# PY32T020xx register map
Vendor: Puya; Series: PY32L0; File version: 1.0.0
CPU: CM0+ r0p1, little endian, no MPU, no FPU, 4 interrupt priority bits
Registers are 32-bit, read-write, reset 0x0 unless marked. A register's access mark holds for its fields unless they carry their own. Offsets are from the block's base; [hi:lo] are bit positions; {n}, {i} and the like mark numbered series.

## PWR — Power control
Base 0x40007000
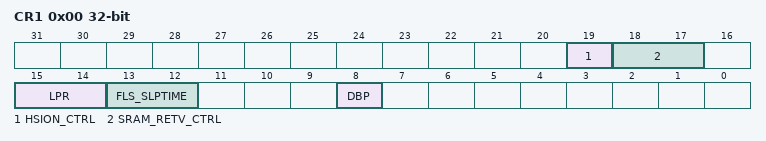
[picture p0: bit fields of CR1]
0x00 CR1 — Power control register 1
  [19] HSION_CTRL
  [18:17] SRAM_RETV_CTRL — sram retev control
  [15:14] LPR — pmu mode control
  [13:12] FLS_SLPTIME — flash sleep time control
  [8] DBP — dbg mode protect enable

## RTC — Real time clock
Base 0x40002800
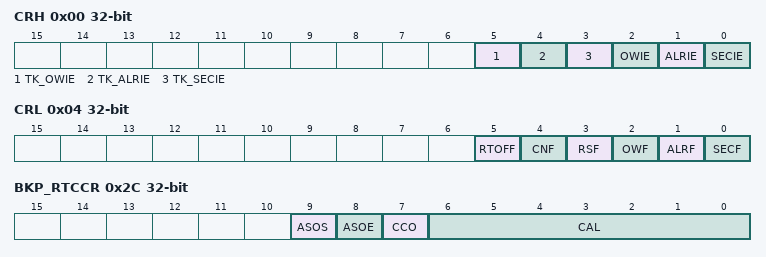
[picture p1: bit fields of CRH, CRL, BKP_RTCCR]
0x00 CRH — RTC Control Register High
  [5] TK_OWIE — TK overflow interrupt allowable bits
  [4] TK_ALRIE — TK alarm interrupt allowed bits
  [3] TK_SECIE — TK sec interrupt allowable bits
  [2] OWIE — Overflow interrupt allow bits
  [1] ALRIE — Alarm interrupt allowed bits
  [0] SECIE — Seconds interrupt allowed bits
0x04 CRL — RTC Control Register Low
  [5] RTOFF ro — RTC operation OFF
  [4] CNF — Configuration flag
  [3] RSF — Registers synchronized flag
  [2] OWF — Overflow flag
  [1] ALRF — Alarm flag
  [0] SECF — Second flag
0x08 PRLH — RTC Prescaler Load Register High
  [5:0] PRL wo — RTC prescaler reload value high
0x0C PRLL — RTC Prescaler Load Register Low
  [15:0] PRL wo — RTC prescaler reload value high
0x10 DIVH — RTC Prescaler Divider Register High
  [3:0] RTC_DIV ro — RTC clock divider
0x14 DIVL — RTC Prescaler Divider Register Low
  [15:0] RTC_DIV ro — RTC clock divider
0x18 CNTH — RTC Counter Register High
  [15:0] RTC_CNT — RTC core counter
0x1C CNTL — RTC Counter Register Low
  [15:0] RTC_CNT — RTC core counter
0x20 ALRH — RTC Alarm Register High
  [15:0] ALR — RTC alarm value
0x24 ALRL — RTC Alarm Register Low
  [15:0] ALR — RTC alarm value
0x2C BKP_RTCCR
  [9] ASOS — Seconds/alarm pulse output select bits
  [8] ASOE — Seconds/alarm pulse output enable bit
  [7] CCO — Calibrate the clock output bits
  [6:0] CAL — Calibration value

## SPI1 — Serial peripheral interface
Base 0x40013000
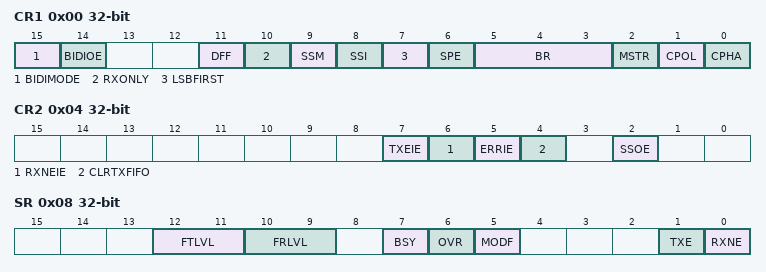
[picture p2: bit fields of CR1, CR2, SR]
0x00 CR1
  [15] BIDIMODE — Bidirectional data mode enable
  [14] BIDIOE — Output enable in bidirectional mode
  [11] DFF — Data frame format
  [10] RXONLY — Receive only
  [9] SSM — Software slave management
  [8] SSI — Internal slave select
  [7] LSBFIRST — Frame Format
  [6] SPE — SPI Enable
  [5:3] BR — Baud Rate Control
  [2] MSTR — Master Selection
  [1] CPOL — Clock Polarity
  [0] CPHA — Clock Phase
0x04 CR2
  [7] TXEIE — Tx buffer Empty Interrupt Enable
  [6] RXNEIE — RX buffer Not Empty Interrupt Enable
  [5] ERRIE — Error Interrupt Enable
  [4] CLRTXFIFO — Clear FIFO
  [2] SSOE — SS Output Enable
0x08 SR
  [12:11] FTLVL ro — FIFO Transmission Level
  [10:9] FRLVL ro — FIFO Reception Level
  [7] BSY ro — Busy flag
  [6] OVR ro — Overrun flag
  [5] MODF — Mode fault
  [1] TXE ro — Transmit buffer Empty
  [0] RXNE ro — Receive buffer Not Empty
0x0C DR
  [15:0] DR — Data Register

## SYSCFG — System configuration controller
Base 0x40010000
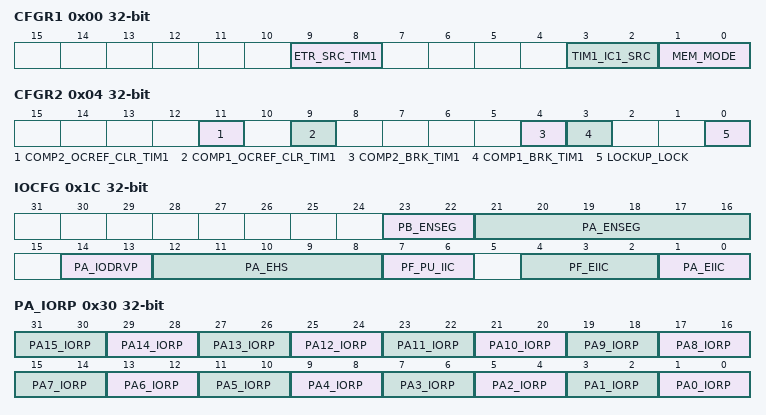
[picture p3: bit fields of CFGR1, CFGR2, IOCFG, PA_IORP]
0x00 CFGR1 — SYSCFG configuration register 1
  [9:8] ETR_SRC_TIM1 — Timer1 ETR Input Selection
  [3:2] TIM1_IC1_SRC — Timer1 CH1 Input Selection
  [1:0] MEM_MODE — Storage Area Mapping Selection
0x04 CFGR2 — SYSCFG configuration register 2
  [11] COMP2_OCREF_CLR_TIM1 — COMP2 as TIM1 ocref_clr Enable
  [9] COMP1_OCREF_CLR_TIM1 — COMP1 as TIM1 ocref_clr Enable
  [4] COMP2_BRK_TIM1 — COMP2 as TIM1 Break Enable
  [3] COMP1_BRK_TIM1 — COMP1 as TIM1 Break Enable
  [0] LOCKUP_LOCK — LOCK_UP as TIM1 Break Enable
0x10 PA_ENS
  [15:0] PA_ENS — Pa Noise filter enable
0x14 PB_ENS
  [3:0] PB_ENS — Pb Noise filter enable
0x18 PF_ENS
  [5:0] PF_ENS — Pf Noise filter enable
0x1C IOCFG
  [23:22] PB_ENSEG — Pb Seg Mode enable
  [21:16] PA_ENSEG — Pa Seg Mode enable
  [14:13] PA_IODRVP — Pa I2C_VCC Output Drive config
  [12:8] PA_EHS — Pa LED IO Conrtol
  [7:6] PF_PU_IIC — Pf I2C Pull-up resistor control enable
  [4:2] PF_EIIC — Pf I2C IO enable
  [1:0] PA_EIIC — Pa I2C IO enable
0x20 PA_ANA2EN
  [15:0] PA_ANA2EN — Pa Analog Noise filter enable
0x24 PB_ANA2EN
  [3:0] PB_ENS — Pb Analog Noise filter enable
0x28 PF_ANA2EN
  [5:0] PF_ANA2EN — Pf Analog Noise filter enable
0x30 PA_IORP
  [2n+1:2n] PA{n}_IORP (n=0..15) — Pa{n} IO pull-up pull-down resistance config
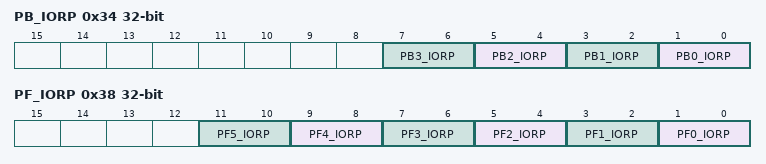
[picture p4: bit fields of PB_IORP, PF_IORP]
0x34 PB_IORP
  [2n+1:2n] PB{n}_IORP (n=0..3) — Pb{n} IO pull-up pull-down resistance config
0x38 PF_IORP
  [2n+1:2n] PF{n}_IORP (n=0..5) — Pf{n} IO pull-up pull-down resistance config
